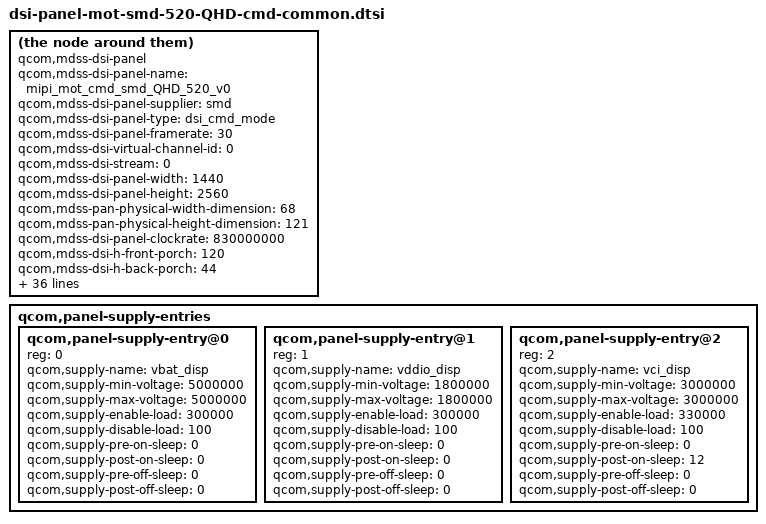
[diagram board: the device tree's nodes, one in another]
/* Copyright (c) 2015, The Linux Foundation. All rights reserved.
 *
 * This program is free software; you can redistribute it and/or modify
 * it under the terms of the GNU General Public License version 2 and
 * only version 2 as published by the Free Software Foundation.
 *
 * This program is distributed in the hope that it will be useful,
 * but WITHOUT ANY WARRANTY; without even the implied warranty of
 * MERCHANTABILITY or FITNESS FOR A PARTICULAR PURPOSE.  See the
 * GNU General Public License for more details.
 */

compatible = "qcom,mdss-dsi-panel";
qcom,mdss-dsi-panel-name = "mipi_mot_cmd_smd_QHD_520_v0";
qcom,mdss-dsi-panel-supplier = "smd";
qcom,mdss-dsi-panel-type = "dsi_cmd_mode";
qcom,mdss-dsi-panel-framerate = <30>;
qcom,mdss-dsi-virtual-channel-id = <0>;
qcom,mdss-dsi-stream = <0>;
qcom,mdss-dsi-panel-width = <1440>;
qcom,mdss-dsi-panel-height = <2560>;
qcom,mdss-pan-physical-width-dimension = <68>;
qcom,mdss-pan-physical-height-dimension = <121>;
qcom,mdss-dsi-panel-clockrate = <830000000>;
qcom,mdss-dsi-h-front-porch = <120>;
qcom,mdss-dsi-h-back-porch = <44>;
qcom,mdss-dsi-h-pulse-width = <16>;
qcom,mdss-dsi-h-sync-skew = <0>;
qcom,mdss-dsi-v-back-porch = <4>;
qcom,mdss-dsi-v-front-porch = <8>;
qcom,mdss-dsi-v-pulse-width = <4>;
qcom,mdss-dsi-h-left-border = <0>;
qcom,mdss-dsi-h-right-border = <0>;
qcom,mdss-dsi-v-top-border = <0>;
qcom,mdss-dsi-v-bottom-border = <0>;
qcom,mdss-dsi-bpp = <24>;
qcom,mdss-dsi-underflow-color = <0xff>;
qcom,mdss-dsi-border-color = <0>;
qcom,mdss-dsi-on-command = [
	/* Unlock level 2 commands */
	39 01 00 00 01 00 03 F0 5A 5A
	/* Unlock level 3 commands */
	39 01 00 00 01 00 03 FC 5A 5A
        /* Configure single-dsi link*/
        15 01 00 00 00 00 02 F2 07
	/* Adjust memory scan time */
	39 01 00 00 01 00 05 FF 00 00 20 00
	/* exit sleep mode */
	05 01 00 00 78 00 02 11 00
	/* enable_te */
	15 01 00 00 01 00 02 35 00
	/* disp_ctrl */
	39 01 00 00 01 00 02 53 20
	/* brightness_ctrl */
	15 01 00 00 01 00 02 51 00
	/* acl_enable_disable_settings */
	39 01 00 00 01 00 02 55 03
	/* Set index for P9 */
	39 01 00 00 01 00 02 B0 08
	/* Turn on memory retention */
	39 01 00 00 01 00 02 F4 03
	/* viewable region */
	39 01 00 00 00 00 05 30 00 00 09 ff
	/* Image up-side down & gate scan inverse */
	15 01 00 00 01 00 02 36 C0
	/* normal col */
	39 01 00 00 00 00 05 2a 00 00 05 9f
	/* normal row */
	39 01 00 00 00 00 05 2b 00 00 09 ff
	/* display on */
	05 01 00 00 00 00 01 29];
qcom,mdss-dsi-off-command = [
	/* display_off */
	05 01 00 00 22 00 01 28
	/* enter sleep mode */
	05 01 00 00 78 00 01 10];
qcom,mdss-dsi-on-command-state = "dsi_lp_mode";
qcom,mdss-dsi-off-command-state = "dsi_lp_mode";
qcom,mdss-dsi-bllp-eof-power-mode; //todo: Check if this can be removed
qcom,mdss-dsi-lane-0-state;
qcom,mdss-dsi-lane-1-state;
qcom,mdss-dsi-lane-2-state;
qcom,mdss-dsi-lane-3-state;
qcom,mdss-dsi-panel-timings = [C9 2E 20 00 5C 5E 24 32 27 03 04 00];
qcom,mdss-dsi-t-clk-post = <0x1B>;
qcom,mdss-dsi-t-clk-pre = <0x26>;
qcom,mdss-dsi-bl-min-level = <1>;
qcom,mdss-dsi-bl-max-level = <255>;
qcom,mdss-dsi-dma-trigger = "trigger_sw";
qcom,mdss-dsi-mdp-trigger = "none";
qcom,mdss-dsi-bl-pmic-control-type = "bl_ctrl_dcs";
qcom,mdss-dsi-reset-sequence = <0 27>, <1 11>;
qcom,mdss-dsi-lp11-init;
qcom,mdss-dsi-tx-eot-append;

/*
 * No TE will be supported for this panel because this panel is
 * configured with transferring frame at 30fps
 */

qcom,panel-supply-entries {
	#address-cells = <1>;
	#size-cells = <0>;

	qcom,panel-supply-entry@0 {
		reg = <0>;
		qcom,supply-name = "vbat_disp";
		qcom,supply-min-voltage = <5000000>;
		qcom,supply-max-voltage = <5000000>;
		qcom,supply-enable-load = <300000>;
		qcom,supply-disable-load = <100>;
		qcom,supply-pre-on-sleep = <0>;
		qcom,supply-post-on-sleep = <0>;
		qcom,supply-pre-off-sleep = <0>;
		qcom,supply-post-off-sleep = <0>;
	};

	qcom,panel-supply-entry@1 {
		reg = <1>;
		qcom,supply-name = "vddio_disp";
		qcom,supply-min-voltage = <1800000>;
		qcom,supply-max-voltage = <1800000>;
		qcom,supply-enable-load = <300000>;
		qcom,supply-disable-load = <100>;
		qcom,supply-pre-on-sleep = <0>;
		qcom,supply-post-on-sleep = <0>;
		qcom,supply-pre-off-sleep = <0>;
		qcom,supply-post-off-sleep = <0>;
	};

	qcom,panel-supply-entry@2 {
		reg = <2>;
		qcom,supply-name = "vci_disp";
		qcom,supply-min-voltage = <3000000>;
		qcom,supply-max-voltage = <3000000>;
		qcom,supply-enable-load = <330000>;
		qcom,supply-disable-load = <100>;
		qcom,supply-pre-on-sleep = <0>;
		qcom,supply-post-on-sleep = <12>;
		qcom,supply-pre-off-sleep = <0>;
		qcom,supply-post-off-sleep = <0>;
	};
};
